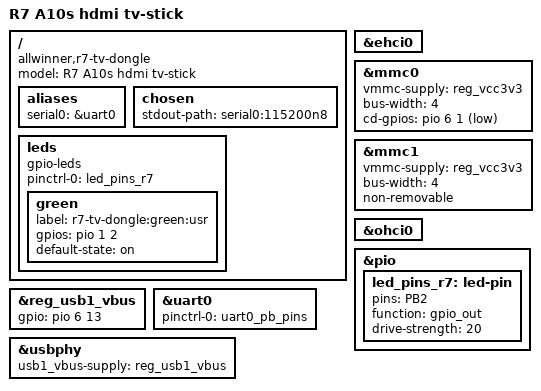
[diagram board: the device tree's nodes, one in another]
/*
 * Copyright 2014 Hans de Goede <hdegoede@redhat.com>
 *
 * This file is dual-licensed: you can use it either under the terms
 * of the GPL or the X11 license, at your option. Note that this dual
 * licensing only applies to this file, and not this project as a
 * whole.
 *
 *  a) This file is free software; you can redistribute it and/or
 *     modify it under the terms of the GNU General Public License as
 *     published by the Free Software Foundation; either version 2 of the
 *     License, or (at your option) any later version.
 *
 *     This file is distributed in the hope that it will be useful,
 *     but WITHOUT ANY WARRANTY; without even the implied warranty of
 *     MERCHANTABILITY or FITNESS FOR A PARTICULAR PURPOSE.  See the
 *     GNU General Public License for more details.
 *
 * Or, alternatively,
 *
 *  b) Permission is hereby granted, free of charge, to any person
 *     obtaining a copy of this software and associated documentation
 *     files (the "Software"), to deal in the Software without
 *     restriction, including without limitation the rights to use,
 *     copy, modify, merge, publish, distribute, sublicense, and/or
 *     sell copies of the Software, and to permit persons to whom the
 *     Software is furnished to do so, subject to the following
 *     conditions:
 *
 *     The above copyright notice and this permission notice shall be
 *     included in all copies or substantial portions of the Software.
 *
 *     THE SOFTWARE IS PROVIDED "AS IS", WITHOUT WARRANTY OF ANY KIND,
 *     EXPRESS OR IMPLIED, INCLUDING BUT NOT LIMITED TO THE WARRANTIES
 *     OF MERCHANTABILITY, FITNESS FOR A PARTICULAR PURPOSE AND
 *     NONINFRINGEMENT. IN NO EVENT SHALL THE AUTHORS OR COPYRIGHT
 *     HOLDERS BE LIABLE FOR ANY CLAIM, DAMAGES OR OTHER LIABILITY,
 *     WHETHER IN AN ACTION OF CONTRACT, TORT OR OTHERWISE, ARISING
 *     FROM, OUT OF OR IN CONNECTION WITH THE SOFTWARE OR THE USE OR
 *     OTHER DEALINGS IN THE SOFTWARE.
 */

/dts-v1/;
#include "sun5i-a10s.dtsi"
#include "sunxi-common-regulators.dtsi"

#include <dt-bindings/gpio/gpio.h>

/ {
	model = "R7 A10s hdmi tv-stick";
	compatible = "allwinner,r7-tv-dongle", "allwinner,sun5i-a10s";

	aliases {
		serial0 = &uart0;
	};

	chosen {
		stdout-path = "serial0:115200n8";
	};

	leds {
		compatible = "gpio-leds";
		pinctrl-names = "default";
		pinctrl-0 = <&led_pins_r7>;

		green {
			label = "r7-tv-dongle:green:usr";
			gpios = <&pio 1 2 GPIO_ACTIVE_HIGH>;
			default-state = "on";
		};
	};
};

&ehci0 {
	status = "okay";
};

&mmc0 {
	vmmc-supply = <&reg_vcc3v3>;
	bus-width = <4>;
	cd-gpios = <&pio 6 1 GPIO_ACTIVE_LOW>; /* PG1 */
	status = "okay";
};

&mmc1 {
	vmmc-supply = <&reg_vcc3v3>;
	bus-width = <4>;
	non-removable;
	status = "okay";
};

&ohci0 {
	status = "okay";
};

&pio {
	led_pins_r7: led-pin {
		pins = "PB2";
		function = "gpio_out";
		drive-strength = <20>;
	};
};

&reg_usb1_vbus {
	gpio = <&pio 6 13 GPIO_ACTIVE_HIGH>;
	status = "okay";
};

&uart0 {
	pinctrl-names = "default";
	pinctrl-0 = <&uart0_pb_pins>;
	status = "okay";
};

&usbphy {
	usb1_vbus-supply = <&reg_usb1_vbus>;
	status = "okay";
};
